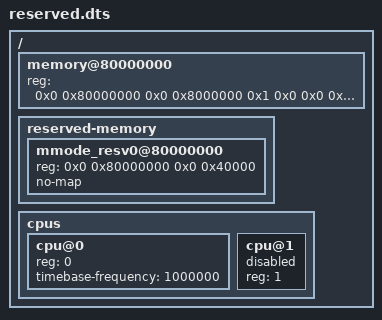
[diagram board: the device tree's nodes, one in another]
/dts-v1/;
/memreserve/ 0x80000000 0x200000;
/ {
	#address-cells = <2>; #size-cells = <2>;
	memory@80000000 { device_type = "memory"; reg = <0x0 0x80000000 0x0 0x8000000 0x1 0x0 0x0 0x10000000>; };
	reserved-memory { #address-cells = <2>; #size-cells = <2>; ranges;
		mmode_resv0@80000000 { reg = <0x0 0x80000000 0x0 0x40000>; no-map; };
	};
	cpus { #address-cells = <1>; #size-cells = <0>;
		cpu@0 { device_type = "cpu"; reg = <0>; status = "okay"; timebase-frequency = <1000000>; };
		cpu@1 { device_type = "cpu"; reg = <1>; status = "disabled"; };
	};
};
